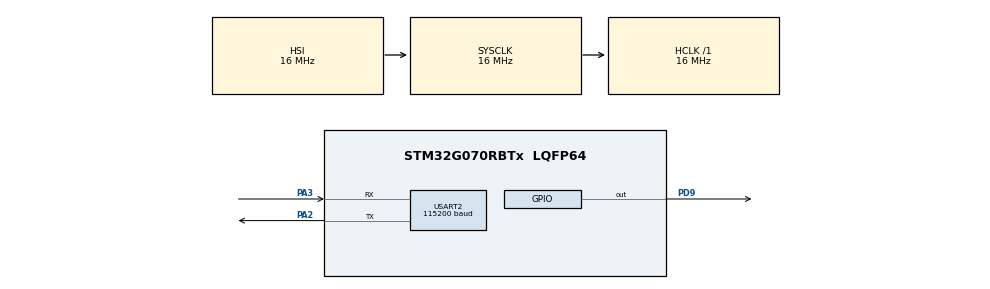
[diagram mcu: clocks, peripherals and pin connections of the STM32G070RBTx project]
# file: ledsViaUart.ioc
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Mcu.Family=STM32G0
Mcu.Name=STM32G070RBTx
Mcu.Package=LQFP64
NVIC.TIM6_IRQn=true\:0\:0\:false\:false\:true\:true\:true\:true
NVIC.USART2_IRQn=true\:0\:0\:false\:false\:true\:true\:true\:true
PA2.GPIO_Speed=GPIO_SPEED_FREQ_HIGH
PA2.Mode=Asynchronous
PA2.Signal=USART2_TX
PA3.GPIO_Speed=GPIO_SPEED_FREQ_HIGH
PA3.Mode=Asynchronous
PA3.Signal=USART2_RX
PD9.Signal=GPIO_Output
PF0-OSC_IN\ (PF0).Mode=HSE-External-Oscillator
PF0-OSC_IN\ (PF0).Signal=RCC_OSC_IN
PF1-OSC_OUT\ (PF1).Mode=HSE-External-Oscillator
PF1-OSC_OUT\ (PF1).Signal=RCC_OSC_OUT
ProjectManager.HeapSize=0x200
ProjectManager.StackSize=0x400
ProjectManager.TargetToolchain=STM32CubeIDE
RCC.ADCFreq_Value=16000000
RCC.AHBFreq_Value=16000000
RCC.CortexFreq_Value=16000000
RCC.EXTERNAL_CLOCK_VALUE=48000
RCC.HCLKFreq_Value=16000000
RCC.HSE_VALUE=12000000
RCC.HSI_VALUE=16000000
RCC.LSE_VALUE=32768
RCC.SYSCLKFreq_VALUE=16000000
RCC.USART1CLockSelection=RCC_USART1CLKSOURCE_SYSCLK
RCC.VCOOutputFreq_Value=128000000
TIM6.Period=1000
TIM6.Prescaler=12000
USART2.BaudRate=115200
USART2.TXFIFOThreshold=TXFIFO_THRESHOLD_1EIGHTHFULL
USART2.VirtualMode-Asynchronous=VM_ASYNC
VP_TIM6_VS_ClockSourceINT.Mode=Enable_Timer
board=custom

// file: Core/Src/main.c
/* USER CODE BEGIN Header */
/**
  ******************************************************************************
  * @file           : main.c
  * @brief          : Main program body
  ******************************************************************************
  * @attention
  *
  * Copyright (c) 2023 STMicroelectronics.
  * All rights reserved.
  *
  * This software is licensed under terms that can be found in the LICENSE file
  * in the root directory of this software component.
  * If no LICENSE file comes with this software, it is provided AS-IS.
  *
  ******************************************************************************
  */
/* USER CODE END Header */
#include "main.h"
#include "tim.h"
#include "usart.h"
#include "gpio.h"

/* USER CODE BEGIN PV */
#define MAXRxMessage 100
#define MAXRxBuf 1

uint8_t RxBuf[MAXRxBuf];
uint8_t RxMessage[MAXRxMessage];

/* USER CODE END PV */

void SystemClock_Config(void);

int main(void)
{

  /* MCU Configuration--------------------------------------------------------*/

  /* Reset of all peripherals, Initializes the Flash interface and the Systick. */
  HAL_Init();

  /* Configure the system clock */
  SystemClock_Config();

  /* Initialize all configured peripherals */
  MX_GPIO_Init();
  MX_TIM6_Init();
  MX_USART2_UART_Init();
  /* USER CODE BEGIN 2 */
  HAL_UART_Receive_IT(&huart2, RxBuf, 1);
  /* USER CODE END 2 */

  /* Infinite loop */
  /* USER CODE BEGIN WHILE */
  while (1)
  {
	ChangeDelayBlinking();
    /* USER CODE END WHILE */

  }
}

void SystemClock_Config(void)
{
  RCC_OscInitTypeDef RCC_OscInitStruct = {0};
  RCC_ClkInitTypeDef RCC_ClkInitStruct = {0};

  /** Configure the main internal regulator output voltage
  */
  HAL_PWREx_ControlVoltageScaling(PWR_REGULATOR_VOLTAGE_SCALE1);

  /** Initializes the RCC Oscillators according to the specified parameters
  * in the RCC_OscInitTypeDef structure.
  */
  RCC_OscInitStruct.OscillatorType = RCC_OSCILLATORTYPE_HSI;
  RCC_OscInitStruct.HSIState = RCC_HSI_ON;
  RCC_OscInitStruct.HSIDiv = RCC_HSI_DIV1;
  RCC_OscInitStruct.HSICalibrationValue = RCC_HSICALIBRATION_DEFAULT;
  RCC_OscInitStruct.PLL.PLLState = RCC_PLL_NONE;
  if (HAL_RCC_OscConfig(&RCC_OscInitStruct) != HAL_OK)
  {
    Error_Handler();
  }

  /** Initializes the CPU, AHB and APB buses clocks
  */
  RCC_ClkInitStruct.ClockType = RCC_CLOCKTYPE_HCLK|RCC_CLOCKTYPE_SYSCLK
                              |RCC_CLOCKTYPE_PCLK1;
  RCC_ClkInitStruct.SYSCLKSource = RCC_SYSCLKSOURCE_HSI;
  RCC_ClkInitStruct.AHBCLKDivider = RCC_SYSCLK_DIV1;
  RCC_ClkInitStruct.APB1CLKDivider = RCC_HCLK_DIV1;

  if (HAL_RCC_ClockConfig(&RCC_ClkInitStruct, FLASH_LATENCY_0) != HAL_OK)
  {
    Error_Handler();
  }
}

void Error_Handler(void)
{
  __disable_irq();
  while (1)
  {
  }
}
